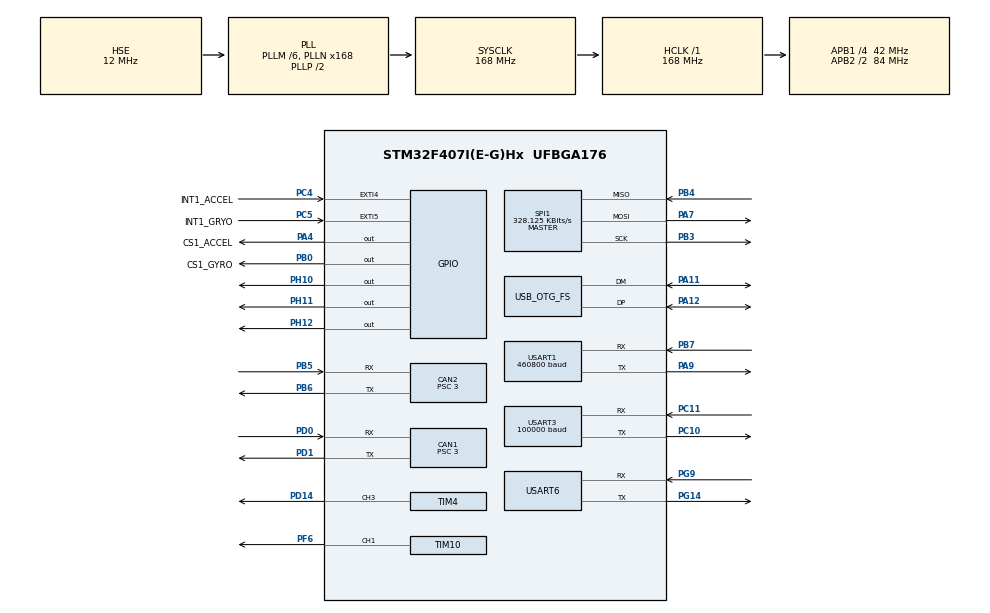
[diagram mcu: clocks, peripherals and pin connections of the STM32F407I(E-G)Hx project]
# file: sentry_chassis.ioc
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CAN1.ABOM=ENABLE
CAN1.BS1=CAN_BS1_11TQ
CAN1.BS2=CAN_BS2_2TQ
CAN1.CalculateBaudRate=1000000
CAN1.CalculateTimeBit=1000
CAN1.CalculateTimeQuantum=71.42857142857143
CAN1.Prescaler=3
CAN2.ABOM=ENABLE
CAN2.BS1=CAN_BS1_11TQ
CAN2.BS2=CAN_BS2_2TQ
CAN2.CalculateBaudRate=1000000
CAN2.CalculateTimeBit=1000
CAN2.CalculateTimeQuantum=71.42857142857143
CAN2.Prescaler=3
Dma.Request0=SPI1_RX
Dma.Request1=SPI1_TX
Dma.Request2=USART3_RX
Dma.Request3=USART6_TX
Dma.Request4=USART6_RX
Dma.Request5=USART1_RX
Dma.Request6=USART1_TX
Dma.SPI1_RX.0.Direction=DMA_PERIPH_TO_MEMORY
Dma.SPI1_RX.0.FIFOMode=DMA_FIFOMODE_DISABLE
Dma.SPI1_RX.0.Instance=DMA2_Stream0
Dma.SPI1_RX.0.MemDataAlignment=DMA_MDATAALIGN_BYTE
Dma.SPI1_RX.0.MemInc=DMA_MINC_ENABLE
Dma.SPI1_RX.0.Mode=DMA_NORMAL
Dma.SPI1_RX.0.PeriphDataAlignment=DMA_PDATAALIGN_BYTE
Dma.SPI1_RX.0.PeriphInc=DMA_PINC_DISABLE
Dma.SPI1_RX.0.Priority=DMA_PRIORITY_LOW
Dma.SPI1_TX.1.Direction=DMA_MEMORY_TO_PERIPH
Dma.SPI1_TX.1.FIFOMode=DMA_FIFOMODE_DISABLE
Dma.SPI1_TX.1.Instance=DMA2_Stream3
Dma.SPI1_TX.1.MemDataAlignment=DMA_MDATAALIGN_BYTE
Dma.SPI1_TX.1.MemInc=DMA_MINC_ENABLE
Dma.SPI1_TX.1.Mode=DMA_NORMAL
Dma.SPI1_TX.1.PeriphDataAlignment=DMA_PDATAALIGN_BYTE
Dma.SPI1_TX.1.PeriphInc=DMA_PINC_DISABLE
Dma.SPI1_TX.1.Priority=DMA_PRIORITY_LOW
Dma.USART1_RX.5.Direction=DMA_PERIPH_TO_MEMORY
Dma.USART1_RX.5.FIFOMode=DMA_FIFOMODE_DISABLE
Dma.USART1_RX.5.Instance=DMA2_Stream2
Dma.USART1_RX.5.MemDataAlignment=DMA_MDATAALIGN_BYTE
Dma.USART1_RX.5.MemInc=DMA_MINC_ENABLE
Dma.USART1_RX.5.Mode=DMA_CIRCULAR
Dma.USART1_RX.5.PeriphDataAlignment=DMA_PDATAALIGN_BYTE
Dma.USART1_RX.5.PeriphInc=DMA_PINC_DISABLE
Dma.USART1_RX.5.Priority=DMA_PRIORITY_LOW
Dma.USART1_TX.6.Direction=DMA_MEMORY_TO_PERIPH
Dma.USART1_TX.6.FIFOMode=DMA_FIFOMODE_DISABLE
Dma.USART1_TX.6.Instance=DMA2_Stream7
Dma.USART1_TX.6.MemDataAlignment=DMA_MDATAALIGN_BYTE
Dma.USART1_TX.6.MemInc=DMA_MINC_ENABLE
Dma.USART1_TX.6.Mode=DMA_NORMAL
Dma.USART1_TX.6.PeriphDataAlignment=DMA_PDATAALIGN_BYTE
Dma.USART1_TX.6.PeriphInc=DMA_PINC_DISABLE
Dma.USART1_TX.6.Priority=DMA_PRIORITY_LOW
Dma.USART3_RX.2.Direction=DMA_PERIPH_TO_MEMORY
Dma.USART3_RX.2.FIFOMode=DMA_FIFOMODE_DISABLE
Dma.USART3_RX.2.Instance=DMA1_Stream1
Dma.USART3_RX.2.MemDataAlignment=DMA_MDATAALIGN_BYTE
Dma.USART3_RX.2.MemInc=DMA_MINC_ENABLE
Dma.USART3_RX.2.Mode=DMA_CIRCULAR
Dma.USART3_RX.2.PeriphDataAlignment=DMA_PDATAALIGN_BYTE
Dma.USART3_RX.2.PeriphInc=DMA_PINC_DISABLE
Dma.USART3_RX.2.Priority=DMA_PRIORITY_LOW
Dma.USART6_RX.4.Direction=DMA_PERIPH_TO_MEMORY
Dma.USART6_RX.4.FIFOMode=DMA_FIFOMODE_DISABLE
Dma.USART6_RX.4.Instance=DMA2_Stream1
Dma.USART6_RX.4.MemDataAlignment=DMA_MDATAALIGN_BYTE
Dma.USART6_RX.4.MemInc=DMA_MINC_ENABLE
Dma.USART6_RX.4.Mode=DMA_CIRCULAR
Dma.USART6_RX.4.PeriphDataAlignment=DMA_PDATAALIGN_BYTE
Dma.USART6_RX.4.PeriphInc=DMA_PINC_DISABLE
Dma.USART6_RX.4.Priority=DMA_PRIORITY_LOW
Dma.USART6_TX.3.Direction=DMA_MEMORY_TO_PERIPH
Dma.USART6_TX.3.FIFOMode=DMA_FIFOMODE_DISABLE
Dma.USART6_TX.3.Instance=DMA2_Stream6
Dma.USART6_TX.3.MemDataAlignment=DMA_MDATAALIGN_BYTE
Dma.USART6_TX.3.MemInc=DMA_MINC_ENABLE
Dma.USART6_TX.3.Mode=DMA_NORMAL
Dma.USART6_TX.3.PeriphDataAlignment=DMA_PDATAALIGN_BYTE
Dma.USART6_TX.3.PeriphInc=DMA_PINC_DISABLE
Dma.USART6_TX.3.Priority=DMA_PRIORITY_LOW
FREERTOS.BinarySemaphores01=RemoteSem,Dynamic,NULL,Depleted;JudgeSem,Dynamic,NULL,Depleted;UartComSem,Dynamic,NULL,Depleted
FREERTOS.Tasks01=ins_task,24,512,INS_Task,As weak,NULL,Dynamic,NULL,NULL;remote_task,8,128,Remote_Task,As weak,NULL,Dynamic,NULL,NULL;watchdog_task,8,128,Watchdog_Task,As weak,NULL,Dynamic,NULL,NULL;judge_task,24,256,Judge_Task,As weak,NULL,Dynamic,NULL,NULL;chassis_task,32,256,Chassis_Task,As weak,NULL,Dynamic,NULL,NULL;cancom_task,8,128,CanCom_Task,As weak,NULL,Dynamic,NULL,NULL;uartcom_task,8,128,UartCom_Task,As weak,NULL,Dynamic,NULL,NULL
FREERTOS.configTOTAL_HEAP_SIZE=32768
Mcu.Family=STM32F4
Mcu.Name=STM32F407I(E-G)Hx
Mcu.Package=UFBGA176
NVIC.CAN1_RX0_IRQn=true\:5\:0\:false\:false\:true\:true\:true\:true\:true
NVIC.CAN1_TX_IRQn=true\:5\:0\:false\:false\:true\:true\:true\:true\:true
NVIC.CAN2_RX1_IRQn=true\:5\:0\:false\:false\:true\:true\:true\:true\:true
NVIC.CAN2_TX_IRQn=true\:5\:0\:false\:false\:true\:true\:true\:true\:true
NVIC.DMA1_Stream1_IRQn=true\:5\:0\:false\:false\:true\:true\:false\:true\:true
NVIC.DMA2_Stream0_IRQn=true\:5\:0\:false\:false\:true\:true\:false\:true\:true
NVIC.DMA2_Stream1_IRQn=true\:5\:0\:false\:false\:true\:true\:false\:true\:true
NVIC.DMA2_Stream2_IRQn=true\:5\:0\:false\:false\:true\:true\:false\:true\:true
NVIC.DMA2_Stream3_IRQn=true\:5\:0\:false\:false\:true\:true\:false\:true\:true
NVIC.DMA2_Stream6_IRQn=true\:5\:0\:false\:false\:true\:true\:false\:true\:true
NVIC.DMA2_Stream7_IRQn=true\:5\:0\:false\:false\:true\:true\:false\:true\:true
NVIC.EXTI4_IRQn=true\:5\:0\:false\:false\:true\:false\:true\:true\:true
NVIC.EXTI9_5_IRQn=true\:5\:0\:false\:false\:true\:false\:true\:true\:true
NVIC.OTG_FS_IRQn=true\:5\:0\:false\:false\:true\:true\:false\:true\:true
NVIC.PriorityGroup=NVIC_PRIORITYGROUP_4
NVIC.TIM7_IRQn=true\:15\:0\:false\:false\:true\:false\:false\:true\:true
NVIC.TimeBase=TIM7_IRQn
NVIC.TimeBaseIP=TIM7
NVIC.USART1_IRQn=true\:5\:0\:false\:false\:true\:true\:true\:true\:true
NVIC.USART3_IRQn=true\:5\:0\:false\:false\:true\:true\:true\:true\:true
NVIC.USART6_IRQn=true\:5\:0\:false\:false\:true\:true\:true\:true\:true
PA11.Mode=Device_Only
PA11.Signal=USB_OTG_FS_DM
PA12.Mode=Device_Only
PA12.Signal=USB_OTG_FS_DP
PA13.Mode=Serial_Wire
PA13.Signal=SYS_JTMS-SWDIO
PA14.Mode=Serial_Wire
PA14.Signal=SYS_JTCK-SWCLK
PA4.GPIO_Label=CS1_ACCEL
PA4.GPIO_PuPd=GPIO_PULLUP
PA4.GPIO_Speed=GPIO_SPEED_FREQ_HIGH
PA4.PinState=GPIO_PIN_SET
PA4.Signal=GPIO_Output
PA7.Mode=Full_Duplex_Master
PA7.Signal=SPI1_MOSI
PA9.Mode=Asynchronous
PA9.Signal=USART1_TX
PB0.GPIO_Label=CS1_GYRO
PB0.GPIO_PuPd=GPIO_PULLUP
PB0.GPIO_Speed=GPIO_SPEED_FREQ_HIGH
PB0.PinState=GPIO_PIN_SET
PB0.Signal=GPIO_Output
PB3.Mode=Full_Duplex_Master
PB3.Signal=SPI1_SCK
PB4.Mode=Full_Duplex_Master
PB4.Signal=SPI1_MISO
PB5.Mode=CAN_Activate
PB5.Signal=CAN2_RX
PB6.Mode=CAN_Activate
PB6.Signal=CAN2_TX
PB7.Mode=Asynchronous
PB7.Signal=USART1_RX
PC10.Mode=Asynchronous
PC10.Signal=USART3_TX
PC11.Mode=Asynchronous
PC11.Signal=USART3_RX
PC14-OSC32_IN.Mode=LSE-External-Oscillator
PC14-OSC32_IN.Signal=RCC_OSC32_IN
PC15-OSC32_OUT.Mode=LSE-External-Oscillator
PC15-OSC32_OUT.Signal=RCC_OSC32_OUT
PC4.GPIO_Label=INT1_ACCEL
PC4.GPIO_ModeDefaultEXTI=GPIO_MODE_IT_FALLING
PC4.GPIO_PuPd=GPIO_PULLUP
PC4.Signal=GPXTI4
PC5.GPIO_Label=INT1_GRYO
PC5.GPIO_ModeDefaultEXTI=GPIO_MODE_IT_FALLING
PC5.GPIO_PuPd=GPIO_PULLUP
PC5.Signal=GPXTI5
PD0.Mode=CAN_Activate
PD0.Signal=CAN1_RX
PD1.Mode=CAN_Activate
PD1.Signal=CAN1_TX
PD14.Signal=S_TIM4_CH3
PF6.GPIO_Speed=GPIO_SPEED_FREQ_HIGH
PF6.Signal=S_TIM10_CH1
PG14.Mode=Asynchronous
PG14.Signal=USART6_TX
PG9.Mode=Asynchronous
PG9.Signal=USART6_RX
PH0-OSC_IN.Mode=HSE-External-Oscillator
PH0-OSC_IN.Signal=RCC_OSC_IN
PH1-OSC_OUT.Mode=HSE-External-Oscillator
PH1-OSC_OUT.Signal=RCC_OSC_OUT
PH10.GPIO_PuPd=GPIO_PULLUP
PH10.Signal=GPIO_Output
PH11.GPIO_PuPd=GPIO_PULLUP
PH11.Signal=GPIO_Output
PH12.GPIO_PuPd=GPIO_PULLUP
PH12.Signal=GPIO_Output
ProjectManager.HeapSize=0x400
ProjectManager.StackSize=0x2000
ProjectManager.TargetToolchain=CMake
RCC.48MHZClocksFreq_Value=48000000
RCC.AHBFreq_Value=168000000
RCC.APB1CLKDivider=RCC_HCLK_DIV4
RCC.APB1Freq_Value=42000000
RCC.APB1TimFreq_Value=84000000
RCC.APB2CLKDivider=RCC_HCLK_DIV2
RCC.APB2Freq_Value=84000000
RCC.APB2TimFreq_Value=168000000
RCC.CortexFreq_Value=168000000
RCC.HCLKFreq_Value=168000000
RCC.HSE_VALUE=12000000
RCC.HSI_VALUE=16000000
RCC.PLLM=6
RCC.PLLN=168
RCC.PLLQ=7
RCC.SYSCLKFreq_VALUE=168000000
RCC.SYSCLKSource=RCC_SYSCLKSOURCE_PLLCLK
RCC.VCOOutputFreq_Value=336000000
SH.S_TIM10_CH1.0=TIM10_CH1,PWM Generation1 CH1
SH.S_TIM4_CH3.0=TIM4_CH3,PWM Generation3 CH3
SPI1.BaudRatePrescaler=SPI_BAUDRATEPRESCALER_256
SPI1.CLKPhase=SPI_PHASE_2EDGE
SPI1.CLKPolarity=SPI_POLARITY_HIGH
SPI1.CalculateBaudRate=328.125 KBits/s
SPI1.Direction=SPI_DIRECTION_2LINES
SPI1.Mode=SPI_MODE_MASTER
SPI1.VirtualType=VM_MASTER
TIM10.Channel=TIM_CHANNEL_1
TIM10.Period=2000-1
TIM10.Prescaler=84-1
TIM4.Channel-PWM\ Generation3\ CH3=TIM_CHANNEL_3
TIM4.Period=500-1
TIM4.Prescaler=84-1
USART1.BaudRate=460800
USART1.VirtualMode=VM_ASYNC
USART3.BaudRate=100000
USART3.Parity=PARITY_EVEN
USART3.VirtualMode=VM_ASYNC
USART3.WordLength=WORDLENGTH_9B
USART6.VirtualMode=VM_ASYNC
USB_DEVICE.CLASS_NAME_FS=CDC
USB_DEVICE.VID-CDC_FS=200
USB_DEVICE.VirtualMode-CDC_FS=Cdc
USB_DEVICE.VirtualModeFS=Cdc_FS
USB_OTG_FS.VirtualMode=Device_Only
VP_FREERTOS_VS_CMSIS_V2.Mode=CMSIS_V2
VP_SYS_VS_tim7.Mode=TIM7
VP_TIM10_VS_ClockSourceINT.Mode=Enable_Timer
VP_TIM4_VS_ClockSourceINT.Mode=Internal
VP_USB_DEVICE_VS_USB_DEVICE_CDC_FS.Mode=CDC_FS
board=custom

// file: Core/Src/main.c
/* USER CODE BEGIN Header */
/**
  ******************************************************************************
  * @file           : main.c
  * @brief          : Main program body
  ******************************************************************************
  * @attention
  *
  * Copyright (c) 2026 STMicroelectronics.
  * All rights reserved.
  *
  * This software is licensed under terms that can be found in the LICENSE file
  * in the root directory of this software component.
  * If no LICENSE file comes with this software, it is provided AS-IS.
  *
  ******************************************************************************
  */
/* USER CODE END Header */
#include "main.h"
#include "cmsis_os.h"
#include "can.h"
#include "dma.h"
#include "spi.h"
#include "tim.h"
#include "usart.h"
#include "usb_device.h"
#include "gpio.h"

/* USER CODE BEGIN Includes */
#include "BMI088driver.h"
#include "user_dwt.h"
/* USER CODE END Includes */

void SystemClock_Config(void);
void MX_FREERTOS_Init(void);

int main(void)
{

  /* MCU Configuration--------------------------------------------------------*/

  /* Reset of all peripherals, Initializes the Flash interface and the Systick. */
  HAL_Init();

  /* Configure the system clock */
  SystemClock_Config();

  /* USER CODE BEGIN SysInit */
  (void)dwt_init();
  /* USER CODE END SysInit */

  /* Initialize all configured peripherals */
  MX_GPIO_Init();
  MX_DMA_Init();
  MX_SPI1_Init();
  MX_TIM10_Init();
  MX_USART3_UART_Init();
  MX_TIM4_Init();
  MX_CAN1_Init();
  MX_CAN2_Init();
  MX_USART6_UART_Init();
  MX_USART1_UART_Init();
  /* USER CODE BEGIN 2 */
  while(BMI088_init());
  /* USER CODE END 2 */

  /* Init scheduler */
  osKernelInitialize();  /* Call init function for freertos objects (in cmsis_os2.c) */
  MX_FREERTOS_Init();

  /* Start scheduler */
  osKernelStart();

  /* We should never get here as control is now taken by the scheduler */

  /* Infinite loop */
  while (1)
  {

  }
}

void SystemClock_Config(void)
{
  RCC_OscInitTypeDef RCC_OscInitStruct = {0};
  RCC_ClkInitTypeDef RCC_ClkInitStruct = {0};

  /** Configure the main internal regulator output voltage
  */
  __HAL_RCC_PWR_CLK_ENABLE();
  __HAL_PWR_VOLTAGESCALING_CONFIG(PWR_REGULATOR_VOLTAGE_SCALE1);

  /** Initializes the RCC Oscillators according to the specified parameters
  * in the RCC_OscInitTypeDef structure.
  */
  RCC_OscInitStruct.OscillatorType = RCC_OSCILLATORTYPE_HSE;
  RCC_OscInitStruct.HSEState = RCC_HSE_ON;
  RCC_OscInitStruct.PLL.PLLState = RCC_PLL_ON;
  RCC_OscInitStruct.PLL.PLLSource = RCC_PLLSOURCE_HSE;
  RCC_OscInitStruct.PLL.PLLM = 6;
  RCC_OscInitStruct.PLL.PLLN = 168;
  RCC_OscInitStruct.PLL.PLLP = RCC_PLLP_DIV2;
  RCC_OscInitStruct.PLL.PLLQ = 7;
  if (HAL_RCC_OscConfig(&RCC_OscInitStruct) != HAL_OK)
  {
    Error_Handler();
  }

  /** Initializes the CPU, AHB and APB buses clocks
  */
  RCC_ClkInitStruct.ClockType = RCC_CLOCKTYPE_HCLK|RCC_CLOCKTYPE_SYSCLK
                              |RCC_CLOCKTYPE_PCLK1|RCC_CLOCKTYPE_PCLK2;
  RCC_ClkInitStruct.SYSCLKSource = RCC_SYSCLKSOURCE_PLLCLK;
  RCC_ClkInitStruct.AHBCLKDivider = RCC_SYSCLK_DIV1;
  RCC_ClkInitStruct.APB1CLKDivider = RCC_HCLK_DIV4;
  RCC_ClkInitStruct.APB2CLKDivider = RCC_HCLK_DIV2;

  if (HAL_RCC_ClockConfig(&RCC_ClkInitStruct, FLASH_LATENCY_5) != HAL_OK)
  {
    Error_Handler();
  }
}

void HAL_TIM_PeriodElapsedCallback(TIM_HandleTypeDef *htim)
{
  if (htim->Instance == TIM7)
  {
    HAL_IncTick();
  }
}

void Error_Handler(void)
{
  __disable_irq();
  while (1)
  {
  }
}

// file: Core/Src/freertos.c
/* USER CODE BEGIN Header */
/**
  ******************************************************************************
  * File Name          : freertos.c
  * Description        : Code for freertos applications
  ******************************************************************************
  * @attention
  *
  * Copyright (c) 2026 STMicroelectronics.
  * All rights reserved.
  *
  * This software is licensed under terms that can be found in the LICENSE file
  * in the root directory of this software component.
  * If no LICENSE file comes with this software, it is provided AS-IS.
  *
  ******************************************************************************
  */
/* USER CODE END Header */

#include "FreeRTOS.h"
#include "task.h"
#include "main.h"
#include "cmsis_os.h"

/* Definitions for ins_task */
osThreadId_t ins_taskHandle;
const osThreadAttr_t ins_task_attributes = {
  .name = "ins_task",
  .stack_size = 512 * 4,
  .priority = (osPriority_t) osPriorityNormal,
};
/* Definitions for remote_task */
osThreadId_t remote_taskHandle;
const osThreadAttr_t remote_task_attributes = {
  .name = "remote_task",
  .stack_size = 128 * 4,
  .priority = (osPriority_t) osPriorityLow,
};
/* Definitions for watchdog_task */
osThreadId_t watchdog_taskHandle;
const osThreadAttr_t watchdog_task_attributes = {
  .name = "watchdog_task",
  .stack_size = 128 * 4,
  .priority = (osPriority_t) osPriorityLow,
};
/* Definitions for judge_task */
osThreadId_t judge_taskHandle;
const osThreadAttr_t judge_task_attributes = {
  .name = "judge_task",
  .stack_size = 256 * 4,
  .priority = (osPriority_t) osPriorityNormal,
};
/* Definitions for chassis_task */
osThreadId_t chassis_taskHandle;
const osThreadAttr_t chassis_task_attributes = {
  .name = "chassis_task",
  .stack_size = 256 * 4,
  .priority = (osPriority_t) osPriorityAboveNormal,
};
/* Definitions for cancom_task */
osThreadId_t cancom_taskHandle;
const osThreadAttr_t cancom_task_attributes = {
  .name = "cancom_task",
  .stack_size = 128 * 4,
  .priority = (osPriority_t) osPriorityLow,
};
/* Definitions for uartcom_task */
osThreadId_t uartcom_taskHandle;
const osThreadAttr_t uartcom_task_attributes = {
  .name = "uartcom_task",
  .stack_size = 128 * 4,
  .priority = (osPriority_t) osPriorityLow,
};
/* Definitions for RemoteSem */
osSemaphoreId_t RemoteSemHandle;
const osSemaphoreAttr_t RemoteSem_attributes = {
  .name = "RemoteSem"
};
/* Definitions for JudgeSem */
osSemaphoreId_t JudgeSemHandle;
const osSemaphoreAttr_t JudgeSem_attributes = {
  .name = "JudgeSem"
};
/* Definitions for UartComSem */
osSemaphoreId_t UartComSemHandle;
const osSemaphoreAttr_t UartComSem_attributes = {
  .name = "UartComSem"
};

void INS_Task(void *argument);
void Remote_Task(void *argument);
void Watchdog_Task(void *argument);
void Judge_Task(void *argument);
void Chassis_Task(void *argument);
void CanCom_Task(void *argument);
void UartCom_Task(void *argument);

extern void MX_USB_DEVICE_Init(void);
void MX_FREERTOS_Init(void); /* (MISRA C 2004 rule 8.1) */

void MX_FREERTOS_Init(void) {

  /* Create the semaphores(s) */
  /* creation of RemoteSem */
  RemoteSemHandle = osSemaphoreNew(1, 0, &RemoteSem_attributes);

  /* creation of JudgeSem */
  JudgeSemHandle = osSemaphoreNew(1, 0, &JudgeSem_attributes);

  /* creation of UartComSem */
  UartComSemHandle = osSemaphoreNew(1, 0, &UartComSem_attributes);

  /* Create the thread(s) */
  /* creation of ins_task */
  ins_taskHandle = osThreadNew(INS_Task, NULL, &ins_task_attributes);

  /* creation of remote_task */
  remote_taskHandle = osThreadNew(Remote_Task, NULL, &remote_task_attributes);

  /* creation of watchdog_task */
  watchdog_taskHandle = osThreadNew(Watchdog_Task, NULL, &watchdog_task_attributes);

  /* creation of judge_task */
  judge_taskHandle = osThreadNew(Judge_Task, NULL, &judge_task_attributes);

  /* creation of chassis_task */
  chassis_taskHandle = osThreadNew(Chassis_Task, NULL, &chassis_task_attributes);

  /* creation of cancom_task */
  cancom_taskHandle = osThreadNew(CanCom_Task, NULL, &cancom_task_attributes);

  /* creation of uartcom_task */
  uartcom_taskHandle = osThreadNew(UartCom_Task, NULL, &uartcom_task_attributes);

}

__weak void INS_Task(void *argument)
{
  /* init code for USB_DEVICE */
  MX_USB_DEVICE_Init();
  for(;;)
  {
    osDelay(1);
  }
}

__weak void Remote_Task(void *argument)
{
  for(;;)
  {
    osDelay(1);
  }
}

__weak void Watchdog_Task(void *argument)
{
  for(;;)
  {
    osDelay(1);
  }
}

__weak void Judge_Task(void *argument)
{
  for(;;)
  {
    osDelay(1);
  }
}

__weak void Chassis_Task(void *argument)
{
  for(;;)
  {
    osDelay(1);
  }
}

__weak void CanCom_Task(void *argument)
{
  for(;;)
  {
    osDelay(1);
  }
}

__weak void UartCom_Task(void *argument)
{
  for(;;)
  {
    osDelay(1);
  }
}
